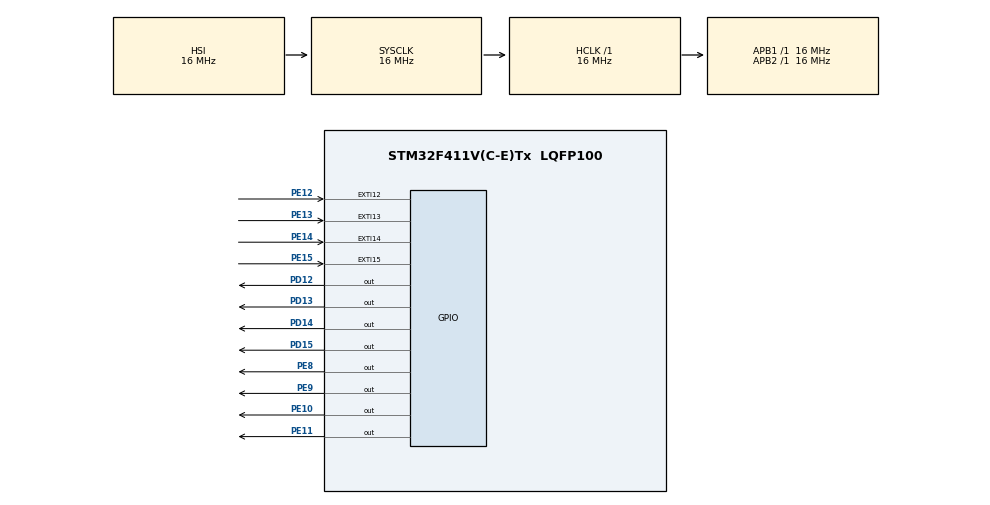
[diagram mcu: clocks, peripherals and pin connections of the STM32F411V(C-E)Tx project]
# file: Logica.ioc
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Mcu.Family=STM32F4
Mcu.Name=STM32F411V(C-E)Tx
Mcu.Package=LQFP100
NVIC.EXTI15_10_IRQn=true\:0\:0\:false\:false\:true\:true
NVIC.PriorityGroup=NVIC_PRIORITYGROUP_4
PD12.Signal=GPIO_Output
PD13.Signal=GPIO_Output
PD14.Signal=GPIO_Output
PD15.Signal=GPIO_Output
PE10.Signal=GPIO_Output
PE11.Signal=GPIO_Output
PE12.Signal=GPXTI12
PE13.Signal=GPXTI13
PE14.Signal=GPXTI14
PE15.Signal=GPXTI15
PE8.Signal=GPIO_Output
PE9.Signal=GPIO_Output
ProjectManager.HeapSize=0x200
ProjectManager.StackSize=0x400
ProjectManager.TargetToolchain=MDK-ARM V5
RCC.AHBFreq_Value=16000000
RCC.APB1Freq_Value=16000000
RCC.APB2Freq_Value=16000000
RCC.CortexFreq_Value=16000000
RCC.HSE_VALUE=25000000
RCC.HSI_VALUE=16000000
RCC.LSE_VALUE=32768
RCC.SYSCLKFreq_VALUE=16000000
RCC.VCOOutputFreq_Value=192000000
board=Logica

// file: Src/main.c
/**
  ******************************************************************************
  * @file           : main.c
  * @brief          : Main program body
  ******************************************************************************
  ** This notice applies to any and all portions of this file
  * that are not between comment pairs USER CODE BEGIN and
  * USER CODE END. Other portions of this file, whether
  * inserted by the user or by software development tools
  * are owned by their respective copyright owners.
  *
  * COPYRIGHT(c) 2018 STMicroelectronics
  *
  * Redistribution and use in source and binary forms, with or without modification,
  * are permitted provided that the following conditions are met:
  *   1. Redistributions of source code must retain the above copyright notice,
  *      this list of conditions and the following disclaimer.
  *   2. Redistributions in binary form must reproduce the above copyright notice,
  *      this list of conditions and the following disclaimer in the documentation
  *      and/or other materials provided with the distribution.
  *   3. Neither the name of STMicroelectronics nor the names of its contributors
  *      may be used to endorse or promote products derived from this software
  *      without specific prior written permission.
  *
  * THIS SOFTWARE IS PROVIDED BY THE COPYRIGHT HOLDERS AND CONTRIBUTORS "AS IS"
  * AND ANY EXPRESS OR IMPLIED WARRANTIES, INCLUDING, BUT NOT LIMITED TO, THE
  * IMPLIED WARRANTIES OF MERCHANTABILITY AND FITNESS FOR A PARTICULAR PURPOSE ARE
  * DISCLAIMED. IN NO EVENT SHALL THE COPYRIGHT HOLDER OR CONTRIBUTORS BE LIABLE
  * FOR ANY DIRECT, INDIRECT, INCIDENTAL, SPECIAL, EXEMPLARY, OR CONSEQUENTIAL
  * DAMAGES (INCLUDING, BUT NOT LIMITED TO, PROCUREMENT OF SUBSTITUTE GOODS OR
  * SERVICES; LOSS OF USE, DATA, OR PROFITS; OR BUSINESS INTERRUPTION) HOWEVER
  * CAUSED AND ON ANY THEORY OF LIABILITY, WHETHER IN CONTRACT, STRICT LIABILITY,
  * OR TORT (INCLUDING NEGLIGENCE OR OTHERWISE) ARISING IN ANY WAY OUT OF THE USE
  * OF THIS SOFTWARE, EVEN IF ADVISED OF THE POSSIBILITY OF SUCH DAMAGE.
  *
  ******************************************************************************
  */
#include "main.h"
#include "stm32f4xx_hal.h"
#include "MY_FLASH.h"

/* USER CODE BEGIN PV */
/* Private variables ---------------------------------------------------------*/

long contador_golpes =0;
int fila =0;
int col =0;
int f_boton_pres =0; // flag boton presionado
int ms_ar=30; //milisegundos anti-rebote
uint8_t id[5] = {0xAA,0xBB,0xCC,0xDD,0xEE};
uint8_t read[32] = {0,0,0,0,0};
/* USER CODE END PV */

void SystemClock_Config(void);
static void MX_GPIO_Init(void);

/* USER CODE BEGIN PFP */
/* Private function prototypes -----------------------------------------------*/
void get_boton(void);
void display_tecla(void);
/* USER CODE END PFP */

int main(void)
{

  /* MCU Configuration----------------------------------------------------------*/

  /* Reset of all peripherals, Initializes the Flash interface and the Systick. */
  HAL_Init();

  /* Configure the system clock */
  SystemClock_Config();

  /* Initialize all configured peripherals */
  MX_GPIO_Init();
  /* USER CODE BEGIN 2 */

	//Elijo el sector con el que voy a trabajar.
	MY_FLASH_SetSectorAddrs(7, 0x08060000);
	MY_FLASH_WriteN(offset,&operarios[op_vacio].condicion,2,DATA_TYPE_8);
			HAL_Delay(5);
	//Escribo un dato en la memoria
	//MY_FLASH_WriteN(0,id, 5, DATA_TYPE_8);
	//Leo los datos en la memoria
	MY_FLASH_ReadN(64,read,26, DATA_TYPE_8);

	HAL_GPIO_WritePin(GPIOE,0x0F00,GPIO_PIN_SET); //Prende E8, 9, 10 y 11 al mismo tiempo.
	HAL_GPIO_WritePin(GPIOD,GPIO_PIN_12,GPIO_PIN_RESET);
	HAL_GPIO_WritePin(GPIOD,GPIO_PIN_13,GPIO_PIN_SET);
	HAL_GPIO_WritePin(GPIOD,GPIO_PIN_14,GPIO_PIN_RESET);
	HAL_GPIO_WritePin(GPIOD,GPIO_PIN_15,GPIO_PIN_SET);

  /* USER CODE END 2 */

  /* Infinite loop */
  while (1)
  {

  }

}

void SystemClock_Config(void)
{

  RCC_OscInitTypeDef RCC_OscInitStruct;
  RCC_ClkInitTypeDef RCC_ClkInitStruct;

    /**Configure the main internal regulator output voltage
    */
  __HAL_RCC_PWR_CLK_ENABLE();

  __HAL_PWR_VOLTAGESCALING_CONFIG(PWR_REGULATOR_VOLTAGE_SCALE1);

    /**Initializes the CPU, AHB and APB busses clocks
    */
  RCC_OscInitStruct.OscillatorType = RCC_OSCILLATORTYPE_HSI;
  RCC_OscInitStruct.HSIState = RCC_HSI_ON;
  RCC_OscInitStruct.HSICalibrationValue = 16;
  RCC_OscInitStruct.PLL.PLLState = RCC_PLL_NONE;
  if (HAL_RCC_OscConfig(&RCC_OscInitStruct) != HAL_OK)
  {
    _Error_Handler(__FILE__, __LINE__);
  }

    /**Initializes the CPU, AHB and APB busses clocks
    */
  RCC_ClkInitStruct.ClockType = RCC_CLOCKTYPE_HCLK|RCC_CLOCKTYPE_SYSCLK
                              |RCC_CLOCKTYPE_PCLK1|RCC_CLOCKTYPE_PCLK2;
  RCC_ClkInitStruct.SYSCLKSource = RCC_SYSCLKSOURCE_HSI;
  RCC_ClkInitStruct.AHBCLKDivider = RCC_SYSCLK_DIV1;
  RCC_ClkInitStruct.APB1CLKDivider = RCC_HCLK_DIV1;
  RCC_ClkInitStruct.APB2CLKDivider = RCC_HCLK_DIV1;

  if (HAL_RCC_ClockConfig(&RCC_ClkInitStruct, FLASH_LATENCY_0) != HAL_OK)
  {
    _Error_Handler(__FILE__, __LINE__);
  }

    /**Configure the Systick interrupt time
    */
  HAL_SYSTICK_Config(HAL_RCC_GetHCLKFreq()/1000);

    /**Configure the Systick
    */
  HAL_SYSTICK_CLKSourceConfig(SYSTICK_CLKSOURCE_HCLK);

  /* SysTick_IRQn interrupt configuration */
  HAL_NVIC_SetPriority(SysTick_IRQn, 0, 0);
}

/** Configure pins as
        * Analog
        * Input
        * Output
        * EVENT_OUT
        * EXTI
*/
static void MX_GPIO_Init(void)
{

  GPIO_InitTypeDef GPIO_InitStruct;

  /* GPIO Ports Clock Enable */
  __HAL_RCC_GPIOE_CLK_ENABLE();
  __HAL_RCC_GPIOD_CLK_ENABLE();

  /*Configure GPIO pin Output Level */
  HAL_GPIO_WritePin(GPIOE, GPIO_PIN_8|GPIO_PIN_9|GPIO_PIN_10|GPIO_PIN_11, GPIO_PIN_RESET);

  /*Configure GPIO pin Output Level */
  HAL_GPIO_WritePin(GPIOD, GPIO_PIN_12|GPIO_PIN_13|GPIO_PIN_14|GPIO_PIN_15, GPIO_PIN_RESET);

  /*Configure GPIO pins : PE8 PE9 PE10 PE11 */
  GPIO_InitStruct.Pin = GPIO_PIN_8|GPIO_PIN_9|GPIO_PIN_10|GPIO_PIN_11;
  GPIO_InitStruct.Mode = GPIO_MODE_OUTPUT_PP;
  GPIO_InitStruct.Pull = GPIO_NOPULL;
  GPIO_InitStruct.Speed = GPIO_SPEED_FREQ_LOW;
  HAL_GPIO_Init(GPIOE, &GPIO_InitStruct);

  /*Configure GPIO pins : PE12 PE13 PE14 PE15 */
  GPIO_InitStruct.Pin = GPIO_PIN_12|GPIO_PIN_13|GPIO_PIN_14|GPIO_PIN_15;
  GPIO_InitStruct.Mode = GPIO_MODE_IT_RISING;
  GPIO_InitStruct.Pull = GPIO_PULLDOWN;
	HAL_GPIO_Init(GPIOE, &GPIO_InitStruct);

	/*Configure GPIO pins : PE7 */
  GPIO_InitStruct.Pin = GPIO_PIN_7;
  GPIO_InitStruct.Mode = GPIO_MODE_IT_FALLING;
  GPIO_InitStruct.Pull = GPIO_PULLUP;
  HAL_GPIO_Init(GPIOE, &GPIO_InitStruct);

  /*Configure GPIO pins : PD12 PD13 PD14 PD15 */
  GPIO_InitStruct.Pin = GPIO_PIN_12|GPIO_PIN_13|GPIO_PIN_14|GPIO_PIN_15;
  GPIO_InitStruct.Mode = GPIO_MODE_OUTPUT_PP;
  GPIO_InitStruct.Pull = GPIO_NOPULL;
  GPIO_InitStruct.Speed = GPIO_SPEED_FREQ_LOW;
  HAL_GPIO_Init(GPIOD, &GPIO_InitStruct);

  /* EXTI interrupt init*/
  HAL_NVIC_SetPriority(EXTI15_10_IRQn, 0, 0);
  HAL_NVIC_EnableIRQ(EXTI15_10_IRQn);
	HAL_NVIC_SetPriority(EXTI9_5_IRQn, 0, 1);
  HAL_NVIC_EnableIRQ(EXTI9_5_IRQn);

}

/* USER CODE BEGIN 4 */
void HAL_GPIO_EXTI_Callback (uint16_t GPIO_Pin){
	if(GPIO_Pin==GPIO_PIN_7){
		contador_golpes++;
		HAL_GPIO_TogglePin(GPIOD,GPIO_PIN_12);
	}else {
			fila=GPIO_Pin;
			ms_ar=30;
			f_boton_pres=1;
	}
}

void HAL_SYSTICK_Callback(void)
{
	if (f_boton_pres==1) ms_ar--;
}

void get_boton(void){

	if (HAL_GPIO_ReadPin(GPIOE,fila)==GPIO_PIN_SET){
		HAL_GPIO_WritePin(GPIOE,GPIO_PIN_8,GPIO_PIN_RESET);
		if (HAL_GPIO_ReadPin(GPIOE,fila)==GPIO_PIN_SET){
			HAL_GPIO_WritePin(GPIOE,GPIO_PIN_9,GPIO_PIN_RESET);
			if (HAL_GPIO_ReadPin(GPIOE,fila)==GPIO_PIN_SET){
				HAL_GPIO_WritePin(GPIOE,GPIO_PIN_10,GPIO_PIN_RESET);
				if (HAL_GPIO_ReadPin(GPIOE,fila)==GPIO_PIN_SET){
					col=4;
				}else col=3;
			}else col=2;
		}else col=1;
	} else col=0;
}

void display_tecla(void){
	char linea1[1];

	switch (fila){
		case 0x00001000:
			switch(col){
				case 1: sprintf(linea1,"1");
				break;
				case 2:	sprintf(linea1,"4");
				break;
				case 3: sprintf(linea1,"7");
				break;
				case 4: sprintf(linea1,"*");
				break;
			}
		break;
		case 0x00002000:
			switch(col){
				case 1: sprintf(linea1,"2");
				break;
				case 2:	sprintf(linea1,"5");
				break;
				case 3: sprintf(linea1,"8");
				break;
				case 4: sprintf(linea1,"0");
				break;
			}
		break;
		case 0x00004000:
			switch(col){
				case 1: sprintf(linea1,"3");
				break;
				case 2:	sprintf(linea1,"6");
				break;
				case 3: sprintf(linea1,"9");
				break;
				case 4: sprintf(linea1,"#");
				break;
			}
		break;
		case 0x00008000:
			switch(col){
				case 1: sprintf(linea1,"A");
				break;
				case 2:	sprintf(linea1,"B");
				break;
				case 3: sprintf(linea1,"C");
				break;
				case 4: sprintf(linea1,"D");
				break;
			}
		break;
	}
	col=0;

}

/* USER CODE END 4 */

void _Error_Handler(char *file, int line)
{
  while(1)
  {
  }
}

/************************ (C) COPYRIGHT STMicroelectronics *****END OF FILE****/
